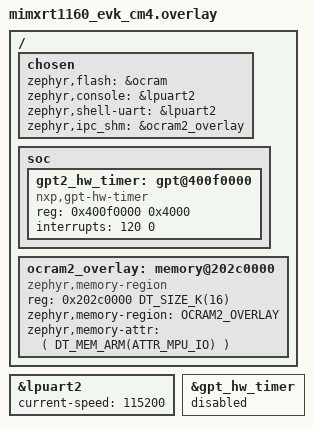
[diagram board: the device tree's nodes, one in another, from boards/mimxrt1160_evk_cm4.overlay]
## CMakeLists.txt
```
#
# Copyright 2023-2024 NXP
#
# SPDX-License-Identifier: BSD-3-Clause
#

cmake_minimum_required(VERSION 3.20.0)

find_package(Zephyr REQUIRED HINTS $ENV{ZEPHYR_BASE})

project(remote_server)

message(STATUS "${BOARD} compiles as remote in this sample")

target_include_directories(app PRIVATE ${CMAKE_CURRENT_SOURCE_DIR}/..)

enable_language(C CXX)

target_include_directories(app PRIVATE
    ${PROJECT_SOURCE_DIR}/..
    ${PROJECT_SOURCE_DIR}/src
    ${PROJECT_SOURCE_DIR}/src/service
)

target_sources(app PRIVATE
    # Main files
    ${PROJECT_SOURCE_DIR}/src/main.cpp
    ${PROJECT_SOURCE_DIR}/src/erpc_error_handler.cpp

    # Generated shim code
    ${PROJECT_SOURCE_DIR}/src/service/c_erpc_matrix_multiply_server.cpp
    ${PROJECT_SOURCE_DIR}/src/service/erpc_matrix_multiply_server.cpp
    ${PROJECT_SOURCE_DIR}/src/service/erpc_matrix_multiply_interface.cpp
)

# Also include this directory into rpmsg_lite library because of project specific include rpsmg_config.h
target_include_directories(rpmsg_lite PRIVATE ${CMAKE_CURRENT_SOURCE_DIR}/..)
# Same for erpc library and erpc_config.h
target_include_directories(erpc PRIVATE ${CMAKE_CURRENT_SOURCE_DIR}/..)
```

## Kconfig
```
# Copyright 2026 NXP
#
# SPDX-License-Identifier: BSD-3-Clause

rsource "../Kconfig"
```

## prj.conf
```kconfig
# C++ Language Support
CONFIG_CPP=y
CONFIG_STD_CPP20=y
CONFIG_NEWLIB_LIBC=y
CONFIG_GLIBCXX_LIBCPP=y

# Compiler
CONFIG_MAIN_STACK_SIZE=4096
CONFIG_HEAP_MEM_POOL_SIZE=8192

# eRPC
CONFIG_ERPC=y
CONFIG_ERPC_TRANSPORT_RPMSG_LITE=y

# RPMSG Lite
CONFIG_IPM=y
CONFIG_EVENTS=y
CONFIG_PRINTK=y
CONFIG_RPMSGLITE=y
CONFIG_RPMSGLITE_QUEUE=y
CONFIG_RPMSGLITE_NS=y
CONFIG_TIMESLICE_SIZE=1

CONFIG_STDOUT_CONSOLE=n
```

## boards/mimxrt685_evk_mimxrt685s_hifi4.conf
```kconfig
#
# Copyright 2026 NXP
#
# SPDX-License-Identifier: Apache-2.0
#

CONFIG_RPMSG_LITE_ENABLE_CACHE=y
```

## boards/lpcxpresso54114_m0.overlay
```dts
/*
 * Copyright (c) 2019 Linaro Limited
 * Copyright 2023 NXP
 *
 * SPDX-License-Identifier: Apache-2.0
 */

/ {
	chosen {
		/*
		 * shared memory reserved for the inter-processor communication
		 */
		zephyr,ipc_shm = &sramx1;
		zephyr,ipc = &mailbox0;
	};

	sramx1:memory@4000000{
		compatible = "mmio-sram";
		reg = <0x4000000 0x8000>;
	};
};
```

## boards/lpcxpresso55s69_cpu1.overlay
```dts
/*
 * Copyright 2023-2024 NXP
 *
 * SPDX-License-Identifier: BSD-3-Clause
 */

/ {
	chosen {
		/*
		 * shared memory reserved for the inter-processor communication
		 */

		zephyr,ipc_shm = &sram4duplicate;
		zephyr,ipc = &mailbox0;
	};

	/* This is a duplication of sram4, workaround */
	sram4duplicate: memory@20040000 {
		compatible = "mmio-sram";
		reg = <0x20040000 DT_SIZE_K(16)>;
	};
};
```

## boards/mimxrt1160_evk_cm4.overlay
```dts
/*
 * Copyright 2023 NXP
 *
 * SPDX-License-Identifier: Apache-2.0
 */

#include <zephyr/dt-bindings/memory-attr/memory-attr-arm.h>

/ {
	/* Switch to lpuart2, since primary core uses lpuart1 */
	chosen {
		zephyr,flash = &ocram;
		zephyr,console = &lpuart2;
		zephyr,shell-uart = &lpuart2;
		zephyr,ipc_shm = &ocram2_overlay;
	};

	soc {
		/delete-node/ gpt@400f0000;

		/* Replace GPT2 with another GPT kernel timer */
		gpt2_hw_timer:gpt@400f0000 {
			compatible = "nxp,gpt-hw-timer";
			reg = <0x400f0000 0x4000>;
			interrupts = <120 0>;
			status = "okay";
		};
	};

	/* OpenAMP fails with full 512K OCRAM2 memory region as shared memory.
	 * Define a subset of the OCRAM2 region for demo to use
	 * Note that shared memory must have specific MPU attributes set
	 */
	ocram2_overlay: memory@202c0000 {
		compatible = "zephyr,memory-region", "mmio-sram";
		reg = <0x202c0000 DT_SIZE_K(16)>;
		zephyr,memory-region="OCRAM2_OVERLAY";
		zephyr,memory-attr = <( DT_MEM_ARM(ATTR_MPU_IO) )>;
	};
};

/* Enable secondary LPUART */
&lpuart2 {
	status = "okay";
	current-speed = <115200>;
};

/* Disable primary GPT timer */
&gpt_hw_timer {
	status = "disabled";
};
```

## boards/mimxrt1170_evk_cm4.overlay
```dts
/*
 * Copyright 2023-2024 NXP
 *
 * SPDX-License-Identifier: BSD-3-Clause
 */

#include <zephyr/dt-bindings/memory-attr/memory-attr-arm.h>

/ {
	/* Switch to lpuart2, since primary core uses lpuart1 */
	chosen {
		zephyr,flash = &ocram;
		zephyr,console = &lpuart2;
		zephyr,shell-uart = &lpuart2;
		zephyr,ipc_shm = &ocram2_overlay;
	};

	soc {
		/delete-node/ gpt@400f0000;

		/* Replace GPT2 with another GPT kernel timer */
		gpt2_hw_timer:gpt@400f0000 {
			compatible = "nxp,gpt-hw-timer";
			reg = <0x400f0000 0x4000>;
			interrupts = <120 0>;
			status = "okay";
		};
	};

	/* OpenAMP fails with full 512K OCRAM2 memory region as shared memory.
	 * Define a subset of the OCRAM2 region for demo to use
	 * Note that shared memory must have specific MPU attributes set
	 */
	ocram2_overlay: memory@202c0000 {
		compatible = "zephyr,memory-region", "mmio-sram";
		reg = <0x202c0000 DT_SIZE_K(16)>;
		zephyr,memory-region="OCRAM2_OVERLAY";
		zephyr,memory-attr = <( DT_MEM_ARM(ATTR_MPU_IO) )>;
	};
};

/* Enable secondary LPUART */
&lpuart2 {
	status = "okay";
	current-speed = <115200>;
};

/* Disable primary GPT timer */
&gpt_hw_timer {
	status = "disabled";
};
```

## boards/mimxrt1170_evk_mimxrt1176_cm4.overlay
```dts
/*
 * Copyright 2023-2024 NXP
 *
 * SPDX-License-Identifier: BSD-3-Clause
 */

#include <zephyr/dt-bindings/memory-attr/memory-attr-arm.h>

/ {
	/* Switch to lpuart2, since primary core uses lpuart1 */
	chosen {
		zephyr,flash = &ocram;
		zephyr,console = &lpuart1;
		zephyr,shell-uart = &lpuart1;
		zephyr,ipc_shm = &ocram2_overlay;
	};

	soc {
		/delete-node/ gpt@400f0000;

		/* Replace GPT2 with another GPT kernel timer */
		gpt2_hw_timer:gpt@400f0000 {
			compatible = "nxp,gpt-hw-timer";
			reg = <0x400f0000 0x4000>;
			interrupts = <120 0>;
			status = "okay";
		};
	};

	/* OpenAMP fails with full 512K OCRAM2 memory region as shared memory.
	 * Define a subset of the OCRAM2 region for demo to use
	 * Note that shared memory must have specific MPU attributes set
	 */
	ocram2_overlay: memory@202c0000 {
		compatible = "zephyr,memory-region", "mmio-sram";
		reg = <0x202c0000 DT_SIZE_K(16)>;
		zephyr,memory-region="OCRAM2_OVERLAY";
		zephyr,memory-attr = <( DT_MEM_ARM(ATTR_MPU_IO) )>;
	};
};

/* Enable secondary LPUART */
&lpuart2 {
	status = "okay";
	current-speed = <115200>;
};

/* Disable primary GPT timer */
&gpt_hw_timer {
	status = "disabled";
};
```

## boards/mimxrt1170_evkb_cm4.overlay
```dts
/*
 * Copyright 2023 NXP
 *
 * SPDX-License-Identifier: Apache-2.0
 */

#include <zephyr/dt-bindings/memory-attr/memory-attr-arm.h>

/ {
	/* Switch to lpuart2, since primary core uses lpuart1 */
	chosen {
		zephyr,flash = &ocram;
		zephyr,console = &lpuart1;
		zephyr,shell-uart = &lpuart1;
		zephyr,ipc_shm = &ocram2_overlay;
	};

	soc {
		/delete-node/ gpt@400f0000;

		/* Replace GPT2 with another GPT kernel timer */
		gpt2_hw_timer:gpt@400f0000 {
			compatible = "nxp,gpt-hw-timer";
			reg = <0x400f0000 0x4000>;
			interrupts = <120 0>;
			status = "okay";
		};
	};

	/* OpenAMP fails with full 512K OCRAM2 memory region as shared memory.
	 * Define a subset of the OCRAM2 region for demo to use
	 * Note that shared memory must have specific MPU attributes set
	 */
	ocram2_overlay: memory@202c0000 {
		compatible = "zephyr,memory-region", "mmio-sram";
		reg = <0x202c0000 DT_SIZE_K(16)>;
		zephyr,memory-region="OCRAM2_OVERLAY";
		zephyr,memory-attr = <( DT_MEM_ARM(ATTR_MPU_IO) )>;
	};
};

/* Enable secondary LPUART */
&lpuart2 {
	status = "okay";
	current-speed = <115200>;
};

/* Disable primary GPT timer */
&gpt_hw_timer {
	status = "disabled";
};
```

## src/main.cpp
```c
/*
 * Copyright 2023-2026 NXP
 *
 * SPDX-License-Identifier: BSD-3-Clause
 */

#include <zephyr/kernel.h>

#include "rpmsg_lite.h"
#include "erpc_server_setup.h"
#include "erpc_matrix_multiply_common.h"
#include "c_erpc_matrix_multiply_server.h"
#include "erpc_error_handler.h"

/*******************************************************************************
 * Definitions
 ******************************************************************************/
#define ERPC_TRANSPORT_RPMSG_LITE_LINK_ID (CONFIG_RPMSG_LITE_LINK_ID)

#define SHM_MEM_ADDR DT_REG_ADDR(DT_CHOSEN(zephyr_ipc_shm))
#define SHM_MEM_SIZE DT_REG_SIZE(DT_CHOSEN(zephyr_ipc_shm))

/*******************************************************************************
 * Prototypes
 ******************************************************************************/

/*******************************************************************************
 * Code
 ******************************************************************************/

/*!
 * @brief erpcMatrixMultiply function implementation.
 *
 * This is the implementation of the erpcMatrixMultiply function called by the primary core.
 *
 * @param matrix1 First matrix
 * @param matrix2 Second matrix
 * @param result_matrix Result matrix
 */
void erpcMatrixMultiply(Matrix matrix1, Matrix matrix2, Matrix result_matrix)
{
    int32_t i, j, k;

    /* Clear the result matrix */
    for (i = 0; i < matrix_size; ++i)
    {
        for (j = 0; j < matrix_size; ++j)
        {
            result_matrix[i][j] = 0;
        }
    }

    /* Multiply two matrices */
    for (i = 0; i < matrix_size; ++i)
    {
        for (j = 0; j < matrix_size; ++j)
        {
            for (k = 0; k < matrix_size; ++k)
            {
                result_matrix[i][j] += matrix1[i][k] * matrix2[k][j];
            }
        }
    }
}

static void SignalReady(void) {}

/*!
 * @brief Main function
 */
int main(void)
{
    uint32_t *shared_memory = (uint32_t *)SHM_MEM_ADDR;

    /* RPMsg-Lite transport layer initialization */
    erpc_transport_t transport;
    erpc_server_t server;

    transport = erpc_transport_rpmsg_lite_rtos_remote_init(101U, 100U, (void *)(char *)shared_memory,
                                                           ERPC_TRANSPORT_RPMSG_LITE_LINK_ID, SignalReady, NULL);

    /* MessageBufferFactory initialization */
    erpc_mbf_t message_buffer_factory;
    message_buffer_factory = erpc_mbf_rpmsg_init(transport);

    /* eRPC server side initialization */
    server = erpc_server_init(transport, message_buffer_factory);

    /* adding the service to the server */
    erpc_service_t service = create_MatrixMultiplyService_service();
    erpc_add_service_to_server(server, service);

    for (;;)
    {
        /* process message */
        erpc_status_t status = erpc_server_poll(server);

        /* handle error status */
        if (status != (erpc_status_t)kErpcStatus_Success)
        {
            /* print error description */
            erpc_error_handler(status, 0);

            /* removing the service from the server */
            erpc_remove_service_from_server(server, service);
            destroy_MatrixMultiplyService_service(service);

            /* stop erpc server */
            erpc_server_stop(server);

            /* print error description */
            erpc_server_deinit(server);

            /* exit program loop */
            break;
        }

        /* do other tasks */
        int32_t i;
        for (i = 0; i < 10000; i++)
        {
        }
    }
    for (;;)
    {
    }
}
```
